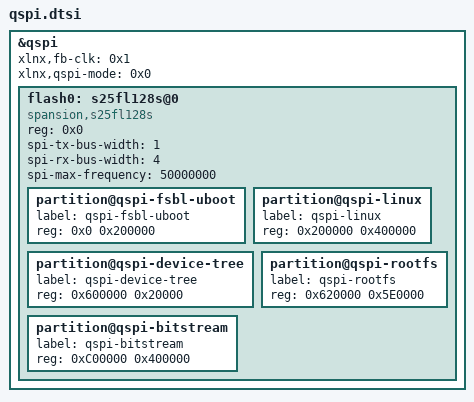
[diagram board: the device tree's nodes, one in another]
/*
 * QSPI Flash specific code
 */

&qspi {
      xlnx,fb-clk = <0x1>;
      xlnx,qspi-mode = <0x0>;
      flash0: s25fl128s@0 {
              compatible = "spansion,s25fl128s", "jedec,spi-nor";
              reg = <0x0>;
              spi-tx-bus-width = <1>;
              spi-rx-bus-width = <4>;
              spi-max-frequency = <50000000>;
              //spi-max-frequency = <100000000>;
              #address-cells = <1>;
              #size-cells = <1>;
              partition@qspi-fsbl-uboot {
                        label = "qspi-fsbl-uboot";
                        reg = <0x0 0x200000>;
              };
              partition@qspi-linux {
                        label = "qspi-linux";
                        reg = <0x200000 0x400000>;
              };
              partition@qspi-device-tree {
                        label = "qspi-device-tree";
                        reg = <0x600000 0x20000>;
              };
              partition@qspi-rootfs {
                        label = "qspi-rootfs";
                        reg = <0x620000 0x5E0000>;
              };
              partition@qspi-bitstream {
                        label = "qspi-bitstream";
                        reg = <0xC00000 0x400000>;
              };
      };
};
